# PIC32CK0512GC00100 register map
Vendor: Microchip Technology; Series: PIC32CKGC00; File version: 0
CPU: CM33 r0p0, little endian, MPU, FPU, DSP, 3 interrupt priority bits, 158 interrupts
Registers are 32-bit, read-write, reset 0x0 unless marked. A register's access mark holds for its fields unless they carry their own. Offsets are from the block's base; [hi:lo] are bit positions; lines under a group give offsets from that group; {n}, {i} and the like mark numbered series; 'fields as' and 'values as' point back to an identical list.

## PORT — Port Module
Base 0x44800000; register names take the prefix PORT_
{0x0+0x80*i} GROUP[{i}] (i=0..3) group
  0x00 DIR — Data Direction
    [31:0] DIR — Port Data Direction
  0x04 DIRCLR — Data Direction Clear
    [31:0] DIRCLR — Port Data Direction Clear
  0x08 DIRSET — Data Direction Set
    [31:0] DIRSET — Port Data Direction Set
  0x0C DIRTGL — Data Direction Toggle
    [31:0] DIRTGL — Port Data Direction Toggle
  0x10 OUT — Data Output Value
    [31:0] OUT — PORT Data Output Value
  0x14 OUTCLR — Data Output Value Clear
    [31:0] OUTCLR — PORT Data Output Value Clear
  0x18 OUTSET — Data Output Value Set
    [31:0] OUTSET — PORT Data Output Value Set
  0x1C OUTTGL — Data Output Value Toggle
    [31:0] OUTTGL — PORT Data Output Value Toggle
  0x20 IN ro — Data Input Value
    [31:0] IN — PORT Data Input Value
  0x24 CTRL — Control
    [31:0] SAMPLING — Input Sampling Mode
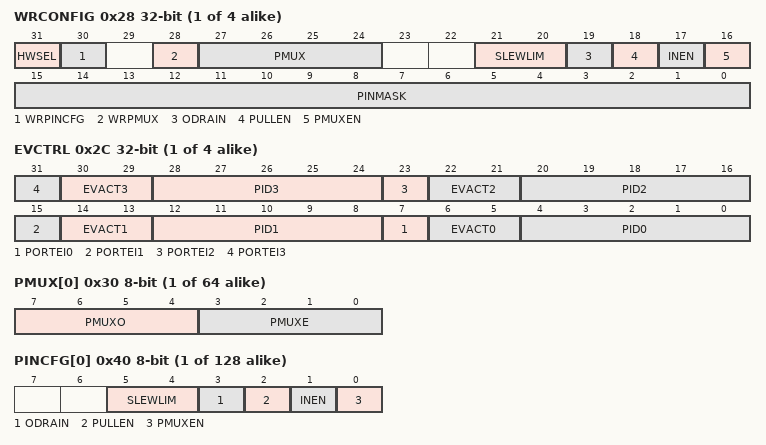
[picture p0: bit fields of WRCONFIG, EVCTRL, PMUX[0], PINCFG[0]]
  0x28 WRCONFIG wo — Write Configuration
    [31] HWSEL — Half-Word Select
    [30] WRPINCFG — Write PINCFG
    [28] WRPMUX — Write PMUX
    [27:24] PMUX — Peripheral Multiplexing
    [21:20] SLEWLIM — Output Driver Slew Rate Selection
    [19] ODRAIN — Open Drain Output
    [18] PULLEN — Pull Enable
    [17] INEN — Input Enable
    [16] PMUXEN — Peripheral Multiplexer Enable
    [15:0] PINMASK — Pin Mask for Multiple Pin Configuration
  0x2C EVCTRL — Event Input Control
    [8n+7] PORTEI{n} (n=0..3) — PORT Event Input Enable {n}
    [30:29] EVACT3 — PORT Event Action 3
    [8n+4:8n] PID{n} (n=0..3) — PORT Event Pin Identifier {n}
    [22:21] EVACT2 — PORT Event Action 2
    [14:13] EVACT1 — PORT Event Action 1
    [6:5] EVACT0 — PORT Event Action 0
      0=OUT (Event output to pin); 1=SET (Set output register of pin on event); 2=CLR (Clear output register of pin on event); 3=TGL (Toggle output register of pin on event)
  {0x30+j} PMUX[{j}] (j=0..15) 8-bit — Peripheral Multiplexing
    [7:4] PMUXO — Peripheral Multiplexing for Odd-Numbered Pin
      0=A (Peripheral function A selected); 1=B (Peripheral function B selected); 2=C (Peripheral function C selected); 3=D (Peripheral function D selected); 4=E (Peripheral function E selected); 5=F (Peripheral function F selected); 6=G (Peripheral function G selected); 7=H (Peripheral function H selected); 8=I (Peripheral function I selected); 9=J (Peripheral function J selected); 10=K (Peripheral function K selected); 11=L (Peripheral function L selected); 12=M (Peripheral function M selected); 15=P (Peripheral function P selected)
    [3:0] PMUXE — Peripheral Multiplexing for Even-Numbered Pin
      values as PMUXO
  {0x40+j} PINCFG[{j}] (j=0..31) 8-bit — Pin Configuration
    [5:4] SLEWLIM — Output Driver Slew Rate Selection
      0=FAST (Slew rate control disabled (fast rise/fall time operation)); 1=SLOW4 (Slew rate control enabled (4x slower)); 2=SLOW8 (Slew rate control enabled (8x slower)); 3=SLOW12 (Slew rate control enabled (12x slower))
    [3] ODRAIN — Open Drain Output
    [2] PULLEN — Pull Enable
    [1] INEN — Input Enable
    [0] PMUXEN — Peripheral Multiplexer Enable

## PRM — Boot ROM Controller
Base 0x4480A000; register names take the prefix PRM_
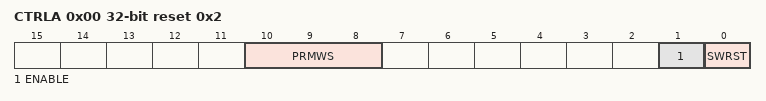
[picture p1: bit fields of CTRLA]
0x00 CTRLA reset 0x2 — CONTROL A REGISTER
  [10:8] PRMWS — ROM ACCESS TIME WAIT STATE
  [1] ENABLE — ENABLE BIT
  [0] SWRST — SOFTWARE RESET BIT

## PTC — Peripheral Touch Controller
Base 0x45014000; register names take the prefix PTC_

## RSTC — Reset Controller
Base 0x4400A000; register names take the prefix RSTC_
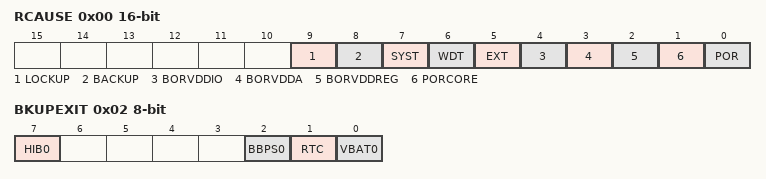
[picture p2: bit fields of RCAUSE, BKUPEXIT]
0x00 RCAUSE 16-bit ro — Reset Cause
  [9] LOCKUP — Lockup Reset
  [8] BACKUP — Backup Reset
  [7] SYST — System Reset Request
  [6] WDT — Watchdog Reset
  [5] EXT — External Reset
  [4] BORVDDIO — Brown Out VDDIO Detector Reset
  [3] BORVDDA — Brown Out VDDA Detector Reset
  [2] BORVDDREG — Brown Out VDDREG Detector Reset
  [1] PORCORE — Brown Out CORE Detector Reset
  [0] POR — Power On Reset
0x02 BKUPEXIT 8-bit ro — Backup Exit Source. Implemented only if RSTC_BACKUP_IMPLEMENTED=1
  [7] HIB0 — Hibernate
  [2] BBPS0 — Battery Backup Power Switch
  [1] RTC — Real Timer Counter Interrupt
  [0] VBAT0 — VBAT failure in backup mode
0x04 DBGCTRL — Debug Control
  [0] LCKUPDIS — Lockup Disable

## Notices in the file
Copyright (c) 2022 Microchip Technology Inc.
SPDX-License-Identifier: Apache-2.0
Licensed under the Apache License, Version 2.0 (the "License");
you may not use this file except in compliance with the License.
You may obtain a copy of the License at
http://www.apache.org/licenses/LICENSE-2.0
Unless required by applicable law or agreed to in writing, software
distributed under the License is distributed on an "AS IS" BASIS,
WITHOUT WARRANTIES OR CONDITIONS OF ANY KIND, either express or implied.
See the License for the specific language governing permissions and
limitations under the License.
